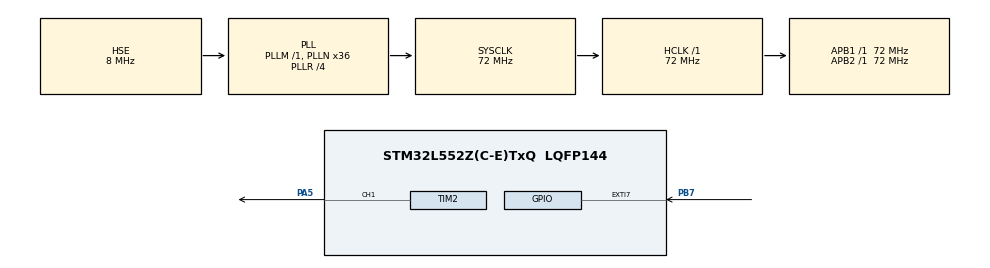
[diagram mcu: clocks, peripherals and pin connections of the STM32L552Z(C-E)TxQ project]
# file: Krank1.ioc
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Mcu.Family=STM32L5
Mcu.Name=STM32L552Z(C-E)TxQ
Mcu.Package=LQFP144
Mcu.TrustZone=disable
NUCLEO-L552ZE-Q.BUTTON=1
NUCLEO-L552ZE-Q.LD1=true
NUCLEO-L552ZE-Q.LD2=true
NUCLEO-L552ZE-Q.LD3=true
NUCLEO-L552ZE-Q.VCP=true
NVIC.EXTI13_IRQn=true\:0\:0\:false\:false\:true\:false\:true\:true
NVIC.PriorityGroup=NVIC_PRIORITYGROUP_3
PA13\ (JTMS/SWDIO).Signal=DEBUG_JTMS-SWDIO
PA14\ (JTCK/SWCLK).Signal=DEBUG_JTCK-SWCLK
PA5.Signal=S_TIM2_CH1
PB3\ (JTDO/TRACESWO).Signal=DEBUG_JTDO-SWO
PB7.Signal=GPXTI7
PC14-OSC32_IN\ (PC14).Signal=RCC_OSC32_IN
PC15-OSC32_OUT\ (PC15).Signal=RCC_OSC32_OUT
PG7.Signal=LPUART1_TX
PG8.Signal=LPUART1_RX
PH0-OSC_IN\ (PH0).Mode=HSE-External-Clock-Source
PH0-OSC_IN\ (PH0).Signal=RCC_OSC_IN
ProjectManager.HeapSize=0x200
ProjectManager.StackSize=0x400
ProjectManager.TargetToolchain=STM32CubeIDE
RCC.ADCCLockSelection=RCC_ADCCLKSOURCE_SYSCLK
RCC.ADCFreq_Value=72000000
RCC.AHBFreq_Value=72000000
RCC.APB1Freq_Value=72000000
RCC.APB1TimFreq_Value=72000000
RCC.APB2Freq_Value=72000000
RCC.APB2TimFreq_Value=72000000
RCC.CK48CLockSelection=RCC_USBCLKSOURCE_HSI48
RCC.CortexFreq_Value=72000000
RCC.HCLKFreq_Value=72000000
RCC.HSE_VALUE=8000000
RCC.HSI48_VALUE=48000000
RCC.HSI_VALUE=16000000
RCC.LSE_VALUE=32768
RCC.MSI_VALUE=4000000
RCC.PLLN=36
RCC.PLLR=RCC_PLLR_DIV4
RCC.PLLSAI1N=24
RCC.PLLSAI1Source=RCC_PLLSAI1SOURCE_HSE
RCC.PLLSAI2Source=RCC_PLLSAI2SOURCE_HSE
RCC.PLLSourceVirtual=RCC_PLLSOURCE_HSE
RCC.RTCClockSelection=RCC_RTCCLKSOURCE_LSE
RCC.SYSCLKFreq_VALUE=72000000
RCC.SYSCLKSource=RCC_SYSCLKSOURCE_PLLCLK
RCC.USBFreq_Value=48000000
RCC.VCOOutputFreq_Value=288000000
SH.S_TIM2_CH1.0=TIM2_CH1,PWM Generation1 CH1
TIM2.Channel-PWM\ Generation1\ CH1=TIM_CHANNEL_1
TIM2.Period=77142
TIM2.Prescaler=69
TIM2.Pulse-PWM\ Generation1\ CH1=500
VP_ICACHE_VS_ICACHE.Mode=DirectMappedCache
VP_NUCLEO-L552ZE-Q_VS_BSP_COMMON.Mode=COMMON
VP_PWR_VS_DBSignals.Mode=DisableDeadBatterySignals
VP_PWR_VS_SECSignals.Mode=Security/Privilege
board=NUCLEO-L552ZE-Q

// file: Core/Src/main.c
/* USER CODE BEGIN Header */
/**
  ******************************************************************************
  * @file           : main.c
  * @brief          : Main program body
  ******************************************************************************
  * @attention
  *
  * Copyright (c) 2026 STMicroelectronics.
  * All rights reserved.
  *
  * This software is licensed under terms that can be found in the LICENSE file
  * in the root directory of this software component.
  * If no LICENSE file comes with this software, it is provided AS-IS.
  *
  ******************************************************************************
  */
/* USER CODE END Header */
#include "main.h"

COM_InitTypeDef BspCOMInit;

TIM_HandleTypeDef htim2;

void SystemClock_Config(void);
static void MX_GPIO_Init(void);
static void MX_ICACHE_Init(void);
static void MX_TIM2_Init(void);

/* USER CODE BEGIN 0 */
void KrankPWM_SetRPM(uint32_t rpm)
{
    uint32_t arr = (1028571UL / (rpm / 60)) - 1;
    TIM2->ARR  = arr;
    TIM2->CCR1 = arr / 2;
}
/* USER CODE END 0 */

int main(void)
{

  /* MCU Configuration--------------------------------------------------------*/

  /* Reset of all peripherals, Initializes the Flash interface and the Systick. */
  HAL_Init();

  /* Configure the system clock */
  SystemClock_Config();

  /* Initialize all configured peripherals */
  MX_GPIO_Init();
  MX_ICACHE_Init();
  MX_TIM2_Init();
  /* USER CODE BEGIN 2 */
  HAL_TIM_PWM_Start(&htim2, TIM_CHANNEL_1);
  KrankPWM_SetRPM(800);
  /* USER CODE END 2 */

  /* Initialize leds */
  BSP_LED_Init(LED_GREEN);
  BSP_LED_Init(LED_BLUE);
  BSP_LED_Init(LED_RED);

  /* Initialize USER push-button, will be used to trigger an interrupt each time it's pressed.*/
  BSP_PB_Init(BUTTON_USER, BUTTON_MODE_EXTI);

  /* Initialize COM1 port (115200, 8 bits (7-bit data + 1 stop bit), no parity */
  BspCOMInit.BaudRate   = 115200;
  BspCOMInit.WordLength = COM_WORDLENGTH_8B;
  BspCOMInit.StopBits   = COM_STOPBITS_1;
  BspCOMInit.Parity     = COM_PARITY_NONE;
  BspCOMInit.HwFlowCtl  = COM_HWCONTROL_NONE;
  if (BSP_COM_Init(COM1, &BspCOMInit) != BSP_ERROR_NONE)
  {
    Error_Handler();
  }

  /* Infinite loop */
  while (1)
  {

  }
}

void SystemClock_Config(void)
{
  RCC_OscInitTypeDef RCC_OscInitStruct = {0};
  RCC_ClkInitTypeDef RCC_ClkInitStruct = {0};

  /** Configure the main internal regulator output voltage
  */
  if (HAL_PWREx_ControlVoltageScaling(PWR_REGULATOR_VOLTAGE_SCALE1) != HAL_OK)
  {
    Error_Handler();
  }

  /** Initializes the RCC Oscillators according to the specified parameters
  * in the RCC_OscInitTypeDef structure.
  */
  RCC_OscInitStruct.OscillatorType = RCC_OSCILLATORTYPE_HSE;
  RCC_OscInitStruct.HSEState = RCC_HSE_BYPASS;
  RCC_OscInitStruct.PLL.PLLState = RCC_PLL_ON;
  RCC_OscInitStruct.PLL.PLLSource = RCC_PLLSOURCE_HSE;
  RCC_OscInitStruct.PLL.PLLM = 1;
  RCC_OscInitStruct.PLL.PLLN = 36;
  RCC_OscInitStruct.PLL.PLLP = RCC_PLLP_DIV7;
  RCC_OscInitStruct.PLL.PLLQ = RCC_PLLQ_DIV2;
  RCC_OscInitStruct.PLL.PLLR = RCC_PLLR_DIV4;
  if (HAL_RCC_OscConfig(&RCC_OscInitStruct) != HAL_OK)
  {
    Error_Handler();
  }

  /** Initializes the CPU, AHB and APB buses clocks
  */
  RCC_ClkInitStruct.ClockType = RCC_CLOCKTYPE_HCLK|RCC_CLOCKTYPE_SYSCLK
                              |RCC_CLOCKTYPE_PCLK1|RCC_CLOCKTYPE_PCLK2;
  RCC_ClkInitStruct.SYSCLKSource = RCC_SYSCLKSOURCE_PLLCLK;
  RCC_ClkInitStruct.AHBCLKDivider = RCC_SYSCLK_DIV1;
  RCC_ClkInitStruct.APB1CLKDivider = RCC_HCLK_DIV1;
  RCC_ClkInitStruct.APB2CLKDivider = RCC_HCLK_DIV1;

  if (HAL_RCC_ClockConfig(&RCC_ClkInitStruct, FLASH_LATENCY_3) != HAL_OK)
  {
    Error_Handler();
  }
}

static void MX_ICACHE_Init(void)
{

  /** Enable instruction cache in 1-way (direct mapped cache)
  */
  if (HAL_ICACHE_ConfigAssociativityMode(ICACHE_1WAY) != HAL_OK)
  {
    Error_Handler();
  }
  if (HAL_ICACHE_Enable() != HAL_OK)
  {
    Error_Handler();
  }

}

static void MX_TIM2_Init(void)
{

  TIM_MasterConfigTypeDef sMasterConfig = {0};
  TIM_OC_InitTypeDef sConfigOC = {0};

  htim2.Instance = TIM2;
  htim2.Init.Prescaler = 69;
  htim2.Init.CounterMode = TIM_COUNTERMODE_UP;
  htim2.Init.Period = 77142;
  htim2.Init.ClockDivision = TIM_CLOCKDIVISION_DIV1;
  htim2.Init.AutoReloadPreload = TIM_AUTORELOAD_PRELOAD_DISABLE;
  if (HAL_TIM_PWM_Init(&htim2) != HAL_OK)
  {
    Error_Handler();
  }
  sMasterConfig.MasterOutputTrigger = TIM_TRGO_RESET;
  sMasterConfig.MasterSlaveMode = TIM_MASTERSLAVEMODE_DISABLE;
  if (HAL_TIMEx_MasterConfigSynchronization(&htim2, &sMasterConfig) != HAL_OK)
  {
    Error_Handler();
  }
  sConfigOC.OCMode = TIM_OCMODE_PWM1;
  sConfigOC.Pulse = 500;
  sConfigOC.OCPolarity = TIM_OCPOLARITY_HIGH;
  sConfigOC.OCFastMode = TIM_OCFAST_DISABLE;
  if (HAL_TIM_PWM_ConfigChannel(&htim2, &sConfigOC, TIM_CHANNEL_1) != HAL_OK)
  {
    Error_Handler();
  }
  HAL_TIM_MspPostInit(&htim2);

}

static void MX_GPIO_Init(void)
{

  /* GPIO Ports Clock Enable */
  __HAL_RCC_GPIOC_CLK_ENABLE();
  __HAL_RCC_GPIOH_CLK_ENABLE();
  __HAL_RCC_GPIOA_CLK_ENABLE();
  __HAL_RCC_GPIOB_CLK_ENABLE();

}

void Error_Handler(void)
{
  __disable_irq();
  while (1)
  {
  }
}
